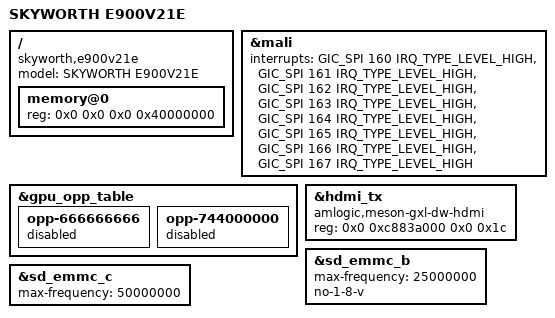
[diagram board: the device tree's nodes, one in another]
// SPDX-License-Identifier: (GPL-2.0+ OR MIT)
/*
 * Copyright (c) 2016 Endless Computers, Inc.
 * Author: Carlo Caione <carlo@endlessm.com>
 */

/dts-v1/;

#include "meson-gxl-s905w-p281.dts"

/ {
	compatible = "skyworth,e900v21e", "amlogic,s905l2", "amlogic,meson-gxl";
	model = "SKYWORTH E900V21E";

	memory@0 {
		device_type = "memory";
		reg = <0x0 0x0 0x0 0x40000000>;
	};
};

// the gpu in the S905L2 has one pp core less
// (i.e. only two in total) than the one in the other S905X/W
&mali {
	status="okay";
	interrupts = <GIC_SPI 160 IRQ_TYPE_LEVEL_HIGH>,
		<GIC_SPI 161 IRQ_TYPE_LEVEL_HIGH>,
		<GIC_SPI 162 IRQ_TYPE_LEVEL_HIGH>,
		<GIC_SPI 163 IRQ_TYPE_LEVEL_HIGH>,
		<GIC_SPI 164 IRQ_TYPE_LEVEL_HIGH>,
		<GIC_SPI 165 IRQ_TYPE_LEVEL_HIGH>,
		<GIC_SPI 166 IRQ_TYPE_LEVEL_HIGH>,
		<GIC_SPI 167 IRQ_TYPE_LEVEL_HIGH>;
	interrupt-names = "gp", "gpmmu", "pp", "pmu",
		"pp0", "ppmmu0", "pp1", "ppmmu1";
};

/*
 * The S905L2 is a lower-binned GXL chip and the Mali voltage rail is
 * not controllable on this board (no mali-supply, so the OPP voltages
 * are never applied). The top OPPs inherited from the S905W/X reference
 * design are unstable: the system crashes at 744MHz. Limit the GPU to
 * 500MHz.
 */
&gpu_opp_table {
	opp-666666666 {
		status = "disabled";
	};

	opp-744000000 {
		status = "disabled";
	};
};

&hdmi_tx {
	status = "okay";
	compatible = "amlogic,meson-gxl-dw-hdmi", "amlogic,meson-gx-dw-hdmi";
	reg = <0x0 0xc883a000 0x0 0x1c>;
};

/* SD card */
&sd_emmc_b {
	status = "okay";
	/delete-property/ sd-uhs-sdr12;
    /delete-property/ sd-uhs-sdr25;
    /delete-property/ sd-uhs-sdr50;
    /delete-property/ sd-uhs-sdr104;
	max-frequency = <25000000>;
	no-1-8-v;	/* 添加此行强制使用 3.3V */
};

/* eMMC */
&sd_emmc_c {
	status = "okay";
	max-frequency = <50000000>;
};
